# MKE14D7 register map
File version: 1.6
Registers are 32-bit, read-write, reset 0x0 unless marked. A register's access mark holds for its fields unless they carry their own. Offsets are from the block's base; [hi:lo] are bit positions; 'fields as' and 'values as' point back to an identical list.

## CRC — Cyclic Redundancy Check
Base 0x40024000; register names take the prefix CRC_
0x00 CRCLL 8-bit reset 0xFF (CRC view) — CRC_CRCLL register.
  [7:0] CRCLL — CRCLL stores the first 8 bits of the 32 bit CRC
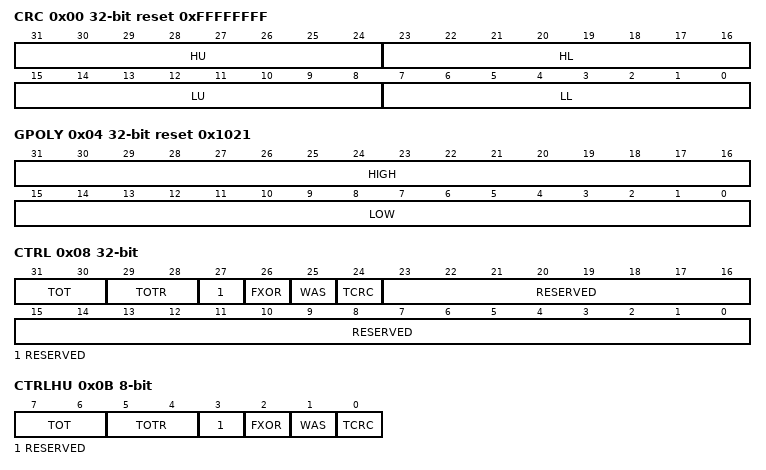
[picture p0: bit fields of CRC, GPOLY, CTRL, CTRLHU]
0x00 CRC reset 0xFFFFFFFF (CRC view) — CRC Data register
  [31:24] HU — CRC High Upper Byte
  [23:16] HL — CRC High Lower Byte
  [15:8] LU — CRC Low Upper Byte
  [7:0] LL — CRC Low Lower Byte
0x00 CRCL 16-bit reset 0xFFFF (CRC view) — CRC_CRCL register.
  [15:0] CRCL — CRCL stores the lower 16 bits of the 16/32 bit CRC
0x01 CRCLU 8-bit reset 0xFF — CRC_CRCLU register.
  [7:0] CRCLU — CRCLL stores the second 8 bits of the 32 bit CRC
0x02 CRCHL 8-bit reset 0xFF (CRC view) — CRC_CRCHL register.
  [7:0] CRCHL — CRCHL stores the third 8 bits of the 32 bit CRC
0x02 CRCH 16-bit reset 0xFFFF (CRC view) — CRC_CRCH register.
  [15:0] CRCH — CRCL stores the high 16 bits of the 16/32 bit CRC
0x03 CRCHU 8-bit reset 0xFF — CRC_CRCHU register.
  [7:0] CRCHU — CRCHU stores the fourth 8 bits of the 32 bit CRC
0x04 GPOLY reset 0x1021 (CRC view) — CRC Polynomial register
  [31:16] HIGH — High Polynominal Half-word
  [15:0] LOW — Low Polynominal Half-word
0x04 GPOLYLL 8-bit reset 0xFF (CRC view) — CRC_GPOLYLL register.
  [7:0] GPOLYLL — POLYLL stores the first 8 bits of the 32 bit CRC
0x04 GPOLYL 16-bit reset 0xFFFF (CRC view) — CRC_GPOLYL register.
  [15:0] GPOLYL — POLYL stores the lower 16 bits of the 16/32 bit CRC polynomial value
0x05 GPOLYLU 8-bit reset 0xFF — CRC_GPOLYLU register.
  [7:0] GPOLYLU — POLYLL stores the second 8 bits of the 32 bit CRC
0x06 GPOLYH 16-bit reset 0xFFFF (CRC view) — CRC_GPOLYH register.
  [15:0] GPOLYH — POLYH stores the high 16 bits of the 16/32 bit CRC polynomial value
0x06 GPOLYHL 8-bit reset 0xFF (CRC view) — CRC_GPOLYHL register.
  [7:0] GPOLYHL — POLYHL stores the third 8 bits of the 32 bit CRC
0x07 GPOLYHU 8-bit reset 0xFF — CRC_GPOLYHU register.
  [7:0] GPOLYHU — POLYHU stores the fourth 8 bits of the 32 bit CRC
0x08 CTRL — CRC Control register
  [31:30] TOT — Type Of Transpose For Writes
    0=No transposition; 1=Bits in bytes are transposed; bytes are not transposed; 2=Both bits in bytes and bytes are transposed; 3=Only bytes are transposed; no bits in a byte are transposed
  [29:28] TOTR — Type Of Transpose For Read
    values as TOT
  [27] RESERVED ro
  [26] FXOR — Complement Read Of CRC Data Register
    0=No XOR on reading; 1=Invert or complement the read value of the CRC Data register
  [25] WAS — Write CRC Data Register As Seed
    0=Writes to the CRC data register are data values; 1=Writes to the CRC data register are seed values
  [24] TCRC
    0=16-bit CRC protocol; 1=32-bit CRC protocol
  [23:0] RESERVED ro
0x0B CTRLHU 8-bit — CRC_CTRLHU register.
  [7:6] TOT
    0=No Transposition; 1=Bits in bytes are transposed, bytes are not transposed; 2=Both bits in bytes and bytes are transposed; 3=Only bytes are transposed; no bits in a byte are transposed
  [5:4] TOTR
    values as TOT
  [3] RESERVED ro
  [2] FXOR
    0=No XOR on reading; 1=Invert or complement the read value of CRC data register
  [1] WAS
    0=Writes to CRC data register are data values; 1=Writes to CRC data reguster are seed values
  [0] TCRC
    0=16-bit CRC protocol; 1=32-bit CRC protocol

## RTC — Real-time counter
Base 0x4002D000; register names take the prefix RTC_
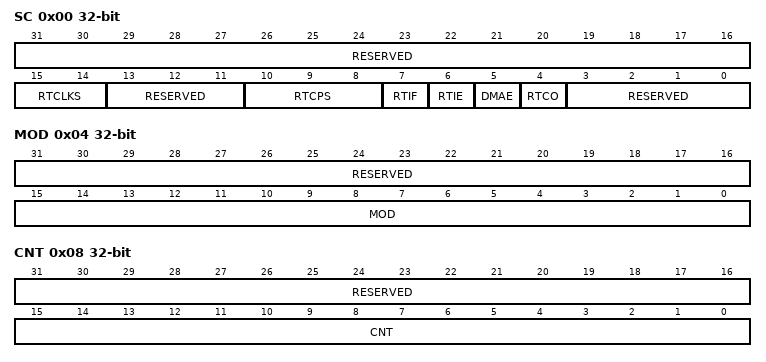
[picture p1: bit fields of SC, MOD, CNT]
0x00 SC — RTC Status and Control Register
  [31:16] RESERVED ro
  [15:14] RTCLKS — Real-Time Clock Source Select
    0=External clock source; 1=Real-time clock source is 1 kHz; 2=Internal clock; 3=Bus clock
  [13:11] RESERVED ro
  [10:8] RTCPS — Real-Time Clock Prescaler Select
    0=Off; 1=If RTCLKS = x0, it is 1; if RTCLKS = x1, it is 128; 2=If RTCLKS = x0, it is 2; if RTCLKS = x1, it is 256; 3=If RTCLKS = x0, it is 4; if RTCLKS = x1, it is 512; 4=If RTCLKS = x0, it is 8; if RTCLKS = x1, it is 1024; 5=If RTCLKS = x0, it is 16; if RTCLKS = x1, it is 2048; 6=If RTCLKS = x0, it is 32; if RTCLKS = x1, it is 100; 7=If RTCLKS = x0, it is 64; if RTCLKS = x1, it is 1000
  [7] RTIF — Real-Time Interrupt Flag
    0=RTC counter has not reached the value in the RTC modulo register; 1=RTC counter has reached the value in the RTC modulo register
  [6] RTIE — Real-Time Interrupt Enable
    0=Real-time interrupt requests are disabled. Use software polling.; 1=Real-time interrupt requests are enabled
  [5] DMAE — DMA Enable
    0=DMA request is disabled. Software polling needed.; 1=DMA request is enabled
  [4] RTCO — Real-Time Counter Output
    0=Real-time counter output disabled; 1=Real-time counter output enabled
  [3:0] RESERVED ro
0x04 MOD — RTC Modulo Register
  [31:16] RESERVED ro
  [15:0] MOD — RTC Modulo
0x08 CNT ro — RTC Counter Register
  [31:16] RESERVED
  [15:0] CNT — RTC Count
